AUTOSAR XML (schema 314)
package /ComponentType
  internal behavior Sa_CDDInterface10_InternalBehavior: component=Sa_CDDInterface10
    timing event CDDInterface10_Init1_InitEvent: start-on-event=CDDInterface10_Init1, period=0
    timing event TMT_CDDInterface10_Per1: start-on-event=CDDInterface10_Per1, period=0.002
    port-api-options:
      enable-take-address=false, indirect-api=false, port=CommOffset
      enable-take-address=false, indirect-api=false, port=ESCOffsCfgSeld
      enable-take-address=false, indirect-api=false, port=IvtrLoaMtgtnEn
      enable-take-address=false, indirect-api=false, port=MotCurrLoaMtgtnEn
      enable-take-address=false, indirect-api=false, port=MRFMtrVel
      enable-take-address=false, indirect-api=false, port=MtrCurr1TempOffset
      enable-take-address=false, indirect-api=false, port=MtrCurr2TempOffset
      enable-take-address=false, indirect-api=false, port=MtrPosPolarity
      enable-take-address=false, indirect-api=false, port=SystemState
      enable-take-address=false, indirect-api=false, port=TurnsCounterSelected
      enable-take-address=false, indirect-api=false, port=Vecu
    runnable CDDInterface10_Init1
      data read access READ_MtrPosPolarity_Cnt_s08: data-element=MtrPosPolarity.Cnt_s08
      data write access WRITE_ESCOffsCfgSeld_Cnt_lgc: data-element=ESCOffsCfgSeld.Cnt_lgc
      data write access WRITE_TurnsCounterSelected_Cnt_lgc: data-element=TurnsCounterSelected.Cnt_lgc
    runnable CDDInterface10_Per1
      8 x data read access:
        READ_CommOffset_Cnt_u16: data-element=CommOffset.Cnt_u16
        READ_IvtrLoaMtgtnEn_Cnt_lgc: data-element=IvtrLoaMtgtnEn.Cnt_lgc
        READ_MotCurrLoaMtgtnEn_Cnt_lgc: data-element=MotCurrLoaMtgtnEn.Cnt_lgc
        READ_MRFMtrVel_MtrRadpS_f32: data-element=MRFMtrVel.MtrRadpS_f32
        READ_MtrCurr1TempOffset_Volt_f32: data-element=MtrCurr1TempOffset.Volt_f32
        READ_MtrCurr2TempOffset_Volt_f32: data-element=MtrCurr2TempOffset.Volt_f32
        READ_MtrPosPolarity_Cnt_s08: data-element=MtrPosPolarity.Cnt_s08
        READ_Vecu_Volt_f32: data-element=Vecu.Volt_f32
      data write access WRITE_ESCOffsCfgSeld_Cnt_lgc: data-element=ESCOffsCfgSeld.Cnt_lgc
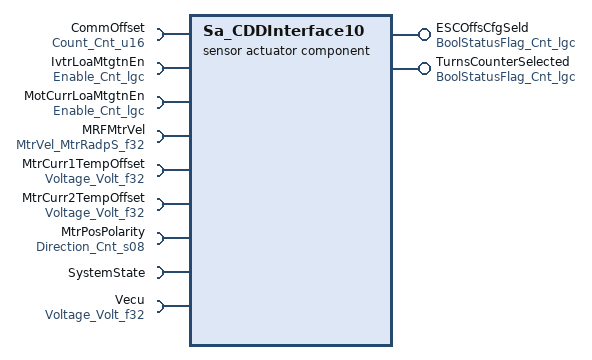
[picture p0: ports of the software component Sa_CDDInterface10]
  sensor actuator software component type Sa_CDDInterface10
    provide port ESCOffsCfgSeld: unqueued-sender-com-spec{data-element=Cnt_lgc, can-invalidate=false, init-value=D_FALSE_CNT_LGC}, provided-interface=BoolStatusFlag_Cnt_lgc
    provide port TurnsCounterSelected: unqueued-sender-com-spec{data-element=Cnt_lgc, can-invalidate=false, init-value=D_FALSE_CNT_LGC}, provided-interface=BoolStatusFlag_Cnt_lgc
    9 x require port:
      CommOffset: unqueued-receiver-com-spec{data-element=Cnt_u16, init-value=D_ZERO_CNT_U16}, required-interface=Count_Cnt_u16
      IvtrLoaMtgtnEn: unqueued-receiver-com-spec{data-element=Cnt_lgc, init-value=D_FALSE_CNT_LGC}, required-interface=Enable_Cnt_lgc
      MotCurrLoaMtgtnEn: unqueued-receiver-com-spec{data-element=Cnt_lgc, init-value=D_FALSE_CNT_LGC}, required-interface=Enable_Cnt_lgc
      MRFMtrVel: unqueued-receiver-com-spec{data-element=MtrRadpS_f32, init-value=D_ZERO_ULS_F32}, required-interface=MtrVel_MtrRadpS_f32
      MtrCurr1TempOffset: unqueued-receiver-com-spec{data-element=Volt_f32, init-value=D_ZERO_ULS_F32}, required-interface=Voltage_Volt_f32
      MtrCurr2TempOffset: unqueued-receiver-com-spec{data-element=Volt_f32, init-value=D_ZERO_ULS_F32}, required-interface=Voltage_Volt_f32
      MtrPosPolarity: unqueued-receiver-com-spec{data-element=Cnt_s08, init-value=D_ZERO_CNT_S8}, required-interface=Direction_Cnt_s08
      SystemState: required-interface=SystemState
      Vecu: unqueued-receiver-com-spec{data-element=Volt_f32, init-value=D_VECUMIN_VOLTS_F32}, required-interface=Voltage_Volt_f32
  swc implementation Sa_CDDInterface10_Implementation: behavior=Sa_CDDInterface10_InternalBehavior
    code-descriptors:
      code Code: type=SRC
